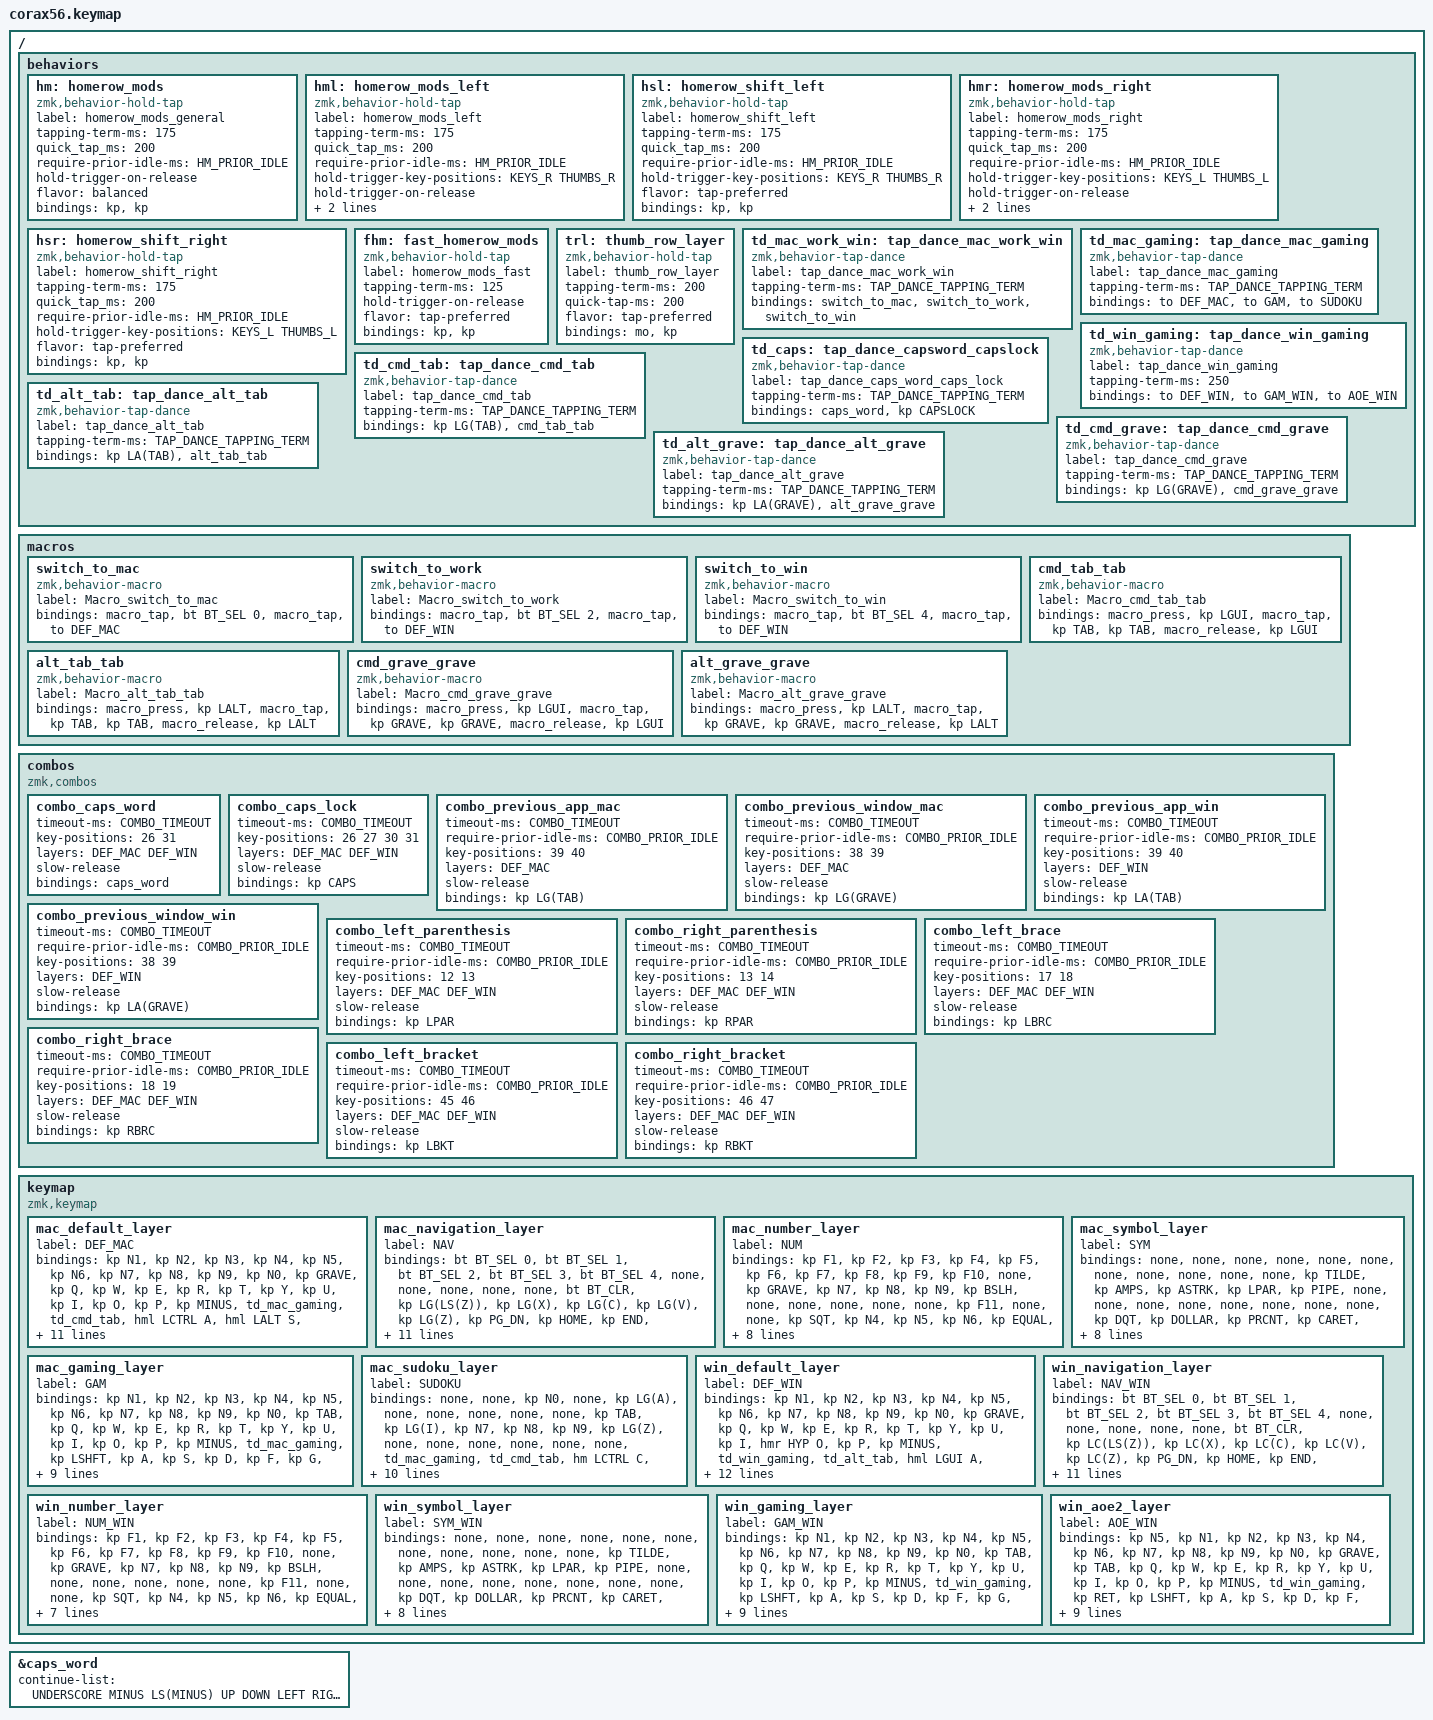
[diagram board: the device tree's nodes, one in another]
#include <behaviors.dtsi>
#include <dt-bindings/zmk/keys.h>
#include <dt-bindings/zmk/bt.h>
#include <dt-bindings/zmk/outputs.h>
#include <dt-bindings/zmk/ext_power.h>

#define DEF_MAC 0
#define NAV     1
#define NUM     2
#define SYM     3
#define GAM     4
#define SUDOKU  5
#define DEF_WIN 6
#define NAV_WIN 7
#define NUM_WIN 8
#define SYM_WIN 9
#define GAM_WIN 10
#define AOE_WIN 11

// Timing constants and Hyper/Meh keys
#define HYP LC(LA(LS(LGUI)))
#define MEH LC(LA(LSHFT))
#define LEADER F12
#define COMBO_TIMEOUT 25
#define COMBO_PRIOR_IDLE 100
#define HM_PRIOR_IDLE 75
#define TAP_DANCE_TAPPING_TERM 250

#define KEYS_L 0 1 2 3 4 10 11 12 13 14 15 22 23 24 25 26 27 28 36 37 38 39 40 41 42 // left-hand keys
#define KEYS_R 5 6 7 8 9 16 17 18 19 20 21 29 30 31 32 33 34 35 43 44 45 46 47 48 49 // right-hand keys
#define THUMBS_L 50 51 52 53 // left-hand thumb keys
#define THUMBS_R 54 55 56 57 // right-hand thumb keys

// Caps word will continue to remain active after these keys
&caps_word {
    continue-list = <UNDERSCORE MINUS LS(MINUS) UP DOWN LEFT RIGHT BSPC DEL>;
};

/ {

    behaviors {

        // Homerow Mods allowing use of modifiers on the home row
        hm: homerow_mods {
            compatible = "zmk,behavior-hold-tap";
            label = "homerow_mods_general";
            #binding-cells = <2>;
            tapping-term-ms = <175>;
            quick_tap_ms = <200>;
            require-prior-idle-ms = <HM_PRIOR_IDLE>;
            hold-trigger-on-release;
            flavor = "balanced";
            bindings = <&kp>, <&kp>;
        };

        hml: homerow_mods_left {
            compatible = "zmk,behavior-hold-tap";
            label = "homerow_mods_left";
            #binding-cells = <2>;
            tapping-term-ms = <175>;
            quick_tap_ms = <200>;
            require-prior-idle-ms = <HM_PRIOR_IDLE>;
            hold-trigger-key-positions = <KEYS_R THUMBS_R>;
            hold-trigger-on-release;
            flavor = "balanced";
            bindings = <&kp>, <&kp>;
        };

        hsl: homerow_shift_left {
            compatible = "zmk,behavior-hold-tap";
            label = "homerow_shift_left";
            #binding-cells = <2>;
            tapping-term-ms = <175>;
            quick_tap_ms = <200>;
            require-prior-idle-ms = <HM_PRIOR_IDLE>;
            hold-trigger-key-positions = <KEYS_R THUMBS_R>;
            flavor = "tap-preferred";
            bindings = <&kp>, <&kp>;
        };

        hmr: homerow_mods_right {
            compatible = "zmk,behavior-hold-tap";
            label = "homerow_mods_right";
            #binding-cells = <2>;
            tapping-term-ms = <175>;
            quick_tap_ms = <200>;
            require-prior-idle-ms = <HM_PRIOR_IDLE>;
            hold-trigger-key-positions = <KEYS_L THUMBS_L>;
            hold-trigger-on-release;
            flavor = "balanced";
            bindings = <&kp>, <&kp>;
        };

        hsr: homerow_shift_right {
            compatible = "zmk,behavior-hold-tap";
            label = "homerow_shift_right";
            #binding-cells = <2>;
            tapping-term-ms = <175>;
            quick_tap_ms = <200>;
            require-prior-idle-ms = <HM_PRIOR_IDLE>;
            hold-trigger-key-positions = <KEYS_L THUMBS_L>;
            flavor = "tap-preferred";
            bindings = <&kp>, <&kp>;
        };

        fhm: fast_homerow_mods {
            compatible = "zmk,behavior-hold-tap";
            label = "homerow_mods_fast";
            #binding-cells = <2>;
            tapping-term-ms = <125>;
            hold-trigger-on-release;
            flavor = "tap-preferred";
            bindings = <&kp>, <&kp>;
        };

        // Layers that are activated when holding a thumb row key
        trl: thumb_row_layer {
            compatible = "zmk,behavior-hold-tap";
            label = "thumb_row_layer";
            #binding-cells = <2>;
            tapping-term-ms = <200>;
            quick-tap-ms = <200>;
            flavor = "tap-preferred";
            bindings = <&mo>, <&kp>;
        };

        // Tap-dance allowing easy switch between mac and windows
        td_mac_work_win: tap_dance_mac_work_win {
            compatible = "zmk,behavior-tap-dance";
            label = "tap_dance_mac_work_win";
            #binding-cells = <0>;
            tapping-term-ms = <TAP_DANCE_TAPPING_TERM>;
            bindings = <&switch_to_mac>, <&switch_to_work>, <&switch_to_win>;
        };

        // Tap-dance allowing easy switch between mac default layer, gaming and sudoku layer
        td_mac_gaming: tap_dance_mac_gaming {
            compatible = "zmk,behavior-tap-dance";
            label = "tap_dance_mac_gaming";
            #binding-cells = <0>;
            tapping-term-ms = <TAP_DANCE_TAPPING_TERM>;
            bindings = <&to DEF_MAC>, <&to GAM>, <&to SUDOKU>;
        };

        // Tap-dance allowing easy switch between windows default layer and gaming layer
        td_win_gaming: tap_dance_win_gaming {
            compatible = "zmk,behavior-tap-dance";
            label = "tap_dance_win_gaming";
            #binding-cells = <0>;
            tapping-term-ms = <250>;
            bindings = <&to DEF_WIN>, <&to GAM_WIN>, <&to AOE_WIN>;
        };

        // Tap-dance allowing easy switch between capsword and capslock
        td_caps: tap_dance_capsword_capslock {
            compatible = "zmk,behavior-tap-dance";
            label = "tap_dance_caps_word_caps_lock";
            #binding-cells = <0>;
            tapping-term-ms = <TAP_DANCE_TAPPING_TERM>;
            bindings = <&caps_word>, <&kp CAPSLOCK>;
        };

        // Tap-dance to quickly switch between last and second-to-last used applications on mac
        td_cmd_tab: tap_dance_cmd_tab {
            compatible = "zmk,behavior-tap-dance";
            label = "tap_dance_cmd_tab";
            #binding-cells = <0>;
            tapping-term-ms = <TAP_DANCE_TAPPING_TERM>;
            bindings = <&kp LG(TAB)>, <&cmd_tab_tab>;
        };

        // Tap-dance to quickly switch between last and second-to-last used applications on windows
        td_alt_tab: tap_dance_alt_tab {
            compatible = "zmk,behavior-tap-dance";
            label = "tap_dance_alt_tab";
            #binding-cells = <0>;
            tapping-term-ms = <TAP_DANCE_TAPPING_TERM>;
            bindings = <&kp LA(TAB)>, <&alt_tab_tab>;
        };

        // Tap-dance to quickly switch between last and second-to-last used window of current application on mac
        td_cmd_grave: tap_dance_cmd_grave {
            compatible = "zmk,behavior-tap-dance";
            label = "tap_dance_cmd_grave";
            #binding-cells = <0>;
            tapping-term-ms = <TAP_DANCE_TAPPING_TERM>;
            bindings = <&kp LG(GRAVE)>, <&cmd_grave_grave>;
        };

        // Tap-dance to quickly switch between last and second-to-last used window of current application on windows
        td_alt_grave: tap_dance_alt_grave {
            compatible = "zmk,behavior-tap-dance";
            label = "tap_dance_alt_grave";
            #binding-cells = <0>;
            tapping-term-ms = <TAP_DANCE_TAPPING_TERM>;
            bindings = <&kp LA(GRAVE)>, <&alt_grave_grave>;
        };

    };

    macros {

        // Macro to select mac bluetooth profile and switch to default mac layer
        switch_to_mac: switch_to_mac {
            label = "Macro_switch_to_mac";
            compatible = "zmk,behavior-macro";
            #binding-cells = <0>;
            bindings = <&macro_tap &bt BT_SEL 0> , <&macro_tap &to DEF_MAC> ;
        };

        // Macro to select mac bluetooth profile and switch to default work layer
        switch_to_work: switch_to_work {
            label = "Macro_switch_to_work";
            compatible = "zmk,behavior-macro";
            #binding-cells = <0>;
            bindings = <&macro_tap &bt BT_SEL 2> , <&macro_tap &to DEF_WIN> ;
        };

        // Macro to select windows bluetooth profile and switch to default windows layer
        switch_to_win: switch_to_win {
            label = "Macro_switch_to_win";
            compatible = "zmk,behavior-macro";
            #binding-cells = <0>;
            bindings = <&macro_tap &bt BT_SEL 4> , <&macro_tap &to DEF_WIN> ;
        };

        // Macro to switch to second-to-last used application on mac
        cmd_tab_tab: cmd_tab_tab {
            label = "Macro_cmd_tab_tab";
            compatible = "zmk,behavior-macro";
            #binding-cells = <0>;
            bindings = <&macro_press &kp LGUI> , <&macro_tap &kp TAB &kp TAB> , <&macro_release &kp LGUI> ;
        };

        // Macro to switch to second-to-last used application on windows
        alt_tab_tab: alt_tab_tab {
            label = "Macro_alt_tab_tab";
            compatible = "zmk,behavior-macro";
            #binding-cells = <0>;
            bindings = <&macro_press &kp LALT> , <&macro_tap &kp TAB &kp TAB> , <&macro_release &kp LALT> ;
        };

        // Macro to switch to second-to-last used window of current application on mac
        cmd_grave_grave: cmd_grave_grave {
            label = "Macro_cmd_grave_grave";
            compatible = "zmk,behavior-macro";
            #binding-cells = <0>;
            bindings = <&macro_press &kp LGUI> , <&macro_tap &kp GRAVE &kp GRAVE> , <&macro_release &kp LGUI> ;
        };

        // Macro to switch to second-to-last used window of current application on windows
        alt_grave_grave: alt_grave_grave {
            label = "Macro_alt_grave_grave";
            compatible = "zmk,behavior-macro";
            #binding-cells = <0>;
            bindings = <&macro_press &kp LALT> , <&macro_tap &kp GRAVE &kp GRAVE> , <&macro_release &kp LALT> ;
        };

    };

    combos {

        compatible = "zmk,combos";

        // Simultaneous D+K : Turn on caps_word
        combo_caps_word {
            timeout-ms = <COMBO_TIMEOUT>;
            key-positions = <26 31>;
            layers = <DEF_MAC DEF_WIN>;
			slow-release;
            bindings = <&caps_word>;
        };

        // Simultaneous D+F+J+K : Toggle Caps Lock
        combo_caps_lock {
            timeout-ms = <COMBO_TIMEOUT>;
            key-positions = <26 27 30 31>;
            layers = <DEF_MAC DEF_WIN>;
			slow-release;
            bindings = <&kp CAPS>;
        };

        // Simultaneous C+V : Switch to previous app on mac
        combo_previous_app_mac {
            timeout-ms = <COMBO_TIMEOUT>;
            require-prior-idle-ms = <COMBO_PRIOR_IDLE>;
            key-positions = <39 40>;
            layers = <DEF_MAC>;
			slow-release;
            bindings = <&kp LG(TAB)>;
        };

        // Simultaneous X+C : Switch to previous window of current app on mac
        combo_previous_window_mac {
            timeout-ms = <COMBO_TIMEOUT>;
            require-prior-idle-ms = <COMBO_PRIOR_IDLE>;
            key-positions = <38 39>;
            layers = <DEF_MAC>;
			slow-release;
            bindings = <&kp LG(GRAVE)>;
        };

        // Simultaneous C+V : Switch to previous app on win
        combo_previous_app_win {
            timeout-ms = <COMBO_TIMEOUT>;
            require-prior-idle-ms = <COMBO_PRIOR_IDLE>;
            key-positions = <39 40>;
            layers = <DEF_WIN>;
			slow-release;
            bindings = <&kp LA(TAB)>;
        };

        // Simultaneous X+C : Switch to previous window of current app on win
        combo_previous_window_win {
            timeout-ms = <COMBO_TIMEOUT>;
            require-prior-idle-ms = <COMBO_PRIOR_IDLE>;
            key-positions = <38 39>;
            layers = <DEF_WIN>;
			slow-release;
            bindings = <&kp LA(GRAVE)>;
        };

        // Simultaneous W+E : Type (
        combo_left_parenthesis {
            timeout-ms = <COMBO_TIMEOUT>;
            require-prior-idle-ms = <COMBO_PRIOR_IDLE>;
            key-positions = <12 13>;
            layers = <DEF_MAC DEF_WIN>;
			slow-release;
            bindings = <&kp LPAR>;
        };

        // Simultaneous E+R : Type )
        combo_right_parenthesis {
            timeout-ms = <COMBO_TIMEOUT>;
            require-prior-idle-ms = <COMBO_PRIOR_IDLE>;
            key-positions = <13 14>;
            layers = <DEF_MAC DEF_WIN>;
			slow-release;
            bindings = <&kp RPAR>;
        };

        // Simultaneous U+I : Type {
        combo_left_brace {
            timeout-ms = <COMBO_TIMEOUT>;
            require-prior-idle-ms = <COMBO_PRIOR_IDLE>;
            key-positions = <17 18>;
            layers = <DEF_MAC DEF_WIN>;
			slow-release;
            bindings = <&kp LBRC>;
        };

        // Simultaneous I+O : Type }
        combo_right_brace {
            timeout-ms = <COMBO_TIMEOUT>;
            require-prior-idle-ms = <COMBO_PRIOR_IDLE>;
            key-positions = <18 19>;
            layers = <DEF_MAC DEF_WIN>;
			slow-release;
            bindings = <&kp RBRC>;
        };

        // Simultaneous m+, : Type [
        combo_left_bracket {
            timeout-ms = <COMBO_TIMEOUT>;
            require-prior-idle-ms = <COMBO_PRIOR_IDLE>;
            key-positions = <45 46>;
            layers = <DEF_MAC DEF_WIN>;
			slow-release;
            bindings = <&kp LBKT>;
        };

        // Simultaneous ,+. : Type ]
        combo_right_bracket {
            timeout-ms = <COMBO_TIMEOUT>;
            require-prior-idle-ms = <COMBO_PRIOR_IDLE>;
            key-positions = <46 47>;
            layers = <DEF_MAC DEF_WIN>;
			slow-release;
            bindings = <&kp RBKT>;
        };

    };

    keymap {
        compatible = "zmk,keymap";

        mac_default_layer {
            label = "DEF_MAC";
            bindings = <
//                                     ┌─────────────┬─────────────┬──────────────────┬─────────────┬─────────────┐                              ┌──────────────┬────────────────┬──────────────────┬─────────────┬─────────────┐
//                                     │      1      │      2      │        3         │      4      │      5      │                              │      6       │       7        │        8         │      9      │      0      │
//                     ┌───────────────┼─────────────┼─────────────┼──────────────────┼─────────────┼─────────────┤                              ├──────────────┼────────────────┼──────────────────┼─────────────┼─────────────┼───┐
//                     │       `       │      Q      │      W      │        E         │      R      │      T      │                              │      Y       │       U        │        I         │      O      │      P      │ - │
//    ┌────────────────┼───────────────┼─────────────┼─────────────┼──────────────────┼─────────────┼─────────────┤                              ├──────────────┼────────────────┼──────────────────┼─────────────┼─────────────┼───┼───┐
//    │ &td_mac_gaming │  &td_cmd_tab  │ &hml lctl A │ &hml lalt S │   &hsl lsft D    │ &hml lgui F │ &hml MEH G  │                              │  &hmr MEH H  │  &hmr rgui J   │   &hsr rsft K    │ &hmr ralt L │ &hmr rctl ; │ ' │ = │
//    └────────────────┼───────────────┼─────────────┼─────────────┼──────────────────┼─────────────┼─────────────┼──────────────┬───────────────┼──────────────┼────────────────┼──────────────────┼─────────────┼─────────────┼───┼───┘
//                     │ &td_cmd_grave │      Z      │      X      │        C         │      V      │      B      │     mute     │     play      │      N       │       M        │        ,         │      .      │      /      │ \ │
//                     └───────────────┴─────────────┴─────────────┼──────────────────┼─────────────┼─────────────┼──────────────┼───────────────┼──────────────┼────────────────┼──────────────────┼─────────────┴─────────────┴───┘
//                                                                 │ &td_mac_work_win │     esc     │ &hm HYP tab │ &trl NAV spc │ &trl NUM bspc │ &trl SYM ent │ &hm HYP LEADER │ &td_mac_work_win │
//                                                                 └──────────────────┴─────────────┴─────────────┴──────────────┴───────────────┴──────────────┴────────────────┴──────────────────┘
                                   &kp N1         &kp N2        &kp N3             &kp N4        &kp N5                                            &kp N6         &kp N7           &kp N8             &kp N9        &kp N0
                   &kp GRAVE       &kp Q          &kp W         &kp E              &kp R         &kp T                                             &kp Y          &kp U            &kp I              &kp O         &kp P             &kp MINUS
  &td_mac_gaming   &td_cmd_tab     &hml LCTRL A   &hml LALT S   &hsl LSHFT D       &hml LGUI F   &hml MEH G                                        &hmr MEH H     &hmr RGUI J      &hsr RSHFT K       &hmr RALT L   &hmr RCTRL SEMI   &kp SQT     &kp EQUAL
                   &td_cmd_grave   &kp Z          &kp X         &kp C              &kp V         &kp B         &kp C_MUTE       &kp C_PLAY_PAUSE   &kp N          &kp M            &kp COMMA          &kp DOT       &kp FSLH          &kp BSLH
                                                                &td_mac_work_win   &kp ESC       &hm HYP TAB   &trl NAV SPACE   &trl NUM BSPC      &trl SYM RET   &hm HYP LEADER   &td_mac_work_win
            >;

            sensor-bindings = <&inc_dec_kp C_VOL_DN C_VOL_UP &inc_dec_kp C_BRI_DN C_BRI_UP>;
        };

		mac_navigation_layer {
            label = "NAV";
            bindings = <
//                            ┌───────────────┬──────────┬──────────┬──────────┬──────────┐             ┌──────────────────┬────────────┬────────────┬──────────────────┬──────┐
//                            │   bt_sel 0    │ bt_sel 1 │ bt_sel 2 │ bt_sel 3 │ bt_sel 4 │             │                  │            │            │                  │      │
//                 ┌──────────┼───────────────┼──────────┼──────────┼──────────┼──────────┤             ├──────────────────┼────────────┼────────────┼──────────────────┼──────┼───────────┐
//                 │  bt_clr  │ lgui(lsft(Z)) │ lgui(X)  │ lgui(C)  │ lgui(V)  │ lgui(Z)  │             │       pgdn       │    home    │    end     │       pgup       │      │ epwr_ tog │
//    ┌────────────┼──────────┼───────────────┼──────────┼──────────┼──────────┼──────────┤             ├──────────────────┼────────────┼────────────┼──────────────────┼──────┼───────────┼─────┐
//    │ &sys_reset │          │     lctl      │   lalt   │   lsft   │   lgui   │   MEH    │             │       left       │    down    │     up     │       rght       │ pscr │           │     │
//    └────────────┼──────────┼───────────────┼──────────┼──────────┼──────────┼──────────┼──────┬──────┼──────────────────┼────────────┼────────────┼──────────────────┼──────┼───────────┼─────┘
//                 │ out_ tog │     bspc      │   esc    │   tab    │   spc    │   ent    │ boot │ boot │ lsft(lalt(left)) │ lalt(left) │ lalt(rght) │ lsft(lalt(rght)) │ pwr  │ term_lock │
//                 └──────────┴───────────────┴──────────┼──────────┼──────────┼──────────┼──────┼──────┼──────────────────┼────────────┼────────────┼──────────────────┴──────┴───────────┘
//                                                       │          │          │          │      │ bspc │       ent        │    del     │            │
//                                                       └──────────┴──────────┴──────────┴──────┴──────┴──────────────────┴────────────┴────────────┘
                              &bt BT_SEL 0    &bt BT_SEL 1   &bt BT_SEL 2   &bt BT_SEL 3   &bt BT_SEL 4                               &none              &none          &none           &none               &none
               &bt BT_CLR     &kp LG(LS(Z))   &kp LG(X)      &kp LG(C)      &kp LG(V)      &kp LG(Z)                                  &kp PG_DN          &kp HOME       &kp END         &kp PG_UP           &none         &ext_power EP_TOG
  &sys_reset   &none          &kp LCTRL       &kp LALT       &kp LSHFT      &kp LGUI       &kp MEH                                    &kp LEFT           &kp DOWN       &kp UP          &kp RIGHT           &kp PSCRN     &none               &none
               &out OUT_TOG   &kp BSPC        &kp ESC        &kp TAB        &kp SPACE      &kp RET        &bootloader   &bootloader   &kp LS(LA(LEFT))   &kp LA(LEFT)   &kp LA(RIGHT)   &kp LS(LA(RIGHT))   &kp C_POWER   &kp C_AL_LOCK
                                                             &none          &none          &none          &none         &kp BSPC      &kp RET            &kp DEL        &none
            >;

            sensor-bindings = <&inc_dec_kp C_VOL_DN C_VOL_UP &inc_dec_kp PG_DN PG_UP>;
        };

		mac_number_layer {
            label = "NUM";
			bindings = <
//                ┌────┬────┬─────┬─────┬────┐           ┌─────┬──────┬──────┬──────┬──────┐
//                │ f1 │ f2 │ f3  │ f4  │ f5 │           │ f6  │  f7  │  f8  │  f9  │ f10  │
//          ┌─────┼────┼────┼─────┼─────┼────┤           ├─────┼──────┼──────┼──────┼──────┼─────┐
//          │     │ `  │ 7  │  8  │  9  │ \  │           │     │      │      │      │      │ f11 │
//    ┌─────┼─────┼────┼────┼─────┼─────┼────┤           ├─────┼──────┼──────┼──────┼──────┼─────┼─────┐
//    │     │     │ '  │ 4  │  5  │  6  │ =  │           │ MEH │ rgui │ rsft │ ralt │ rctl │     │ f12 │
//    └─────┼─────┼────┼────┼─────┼─────┼────┼─────┬─────┼─────┼──────┼──────┼──────┼──────┼─────┼─────┘
//          │     │ [  │ 1  │  2  │  3  │ ]  │     │     │     │      │      │      │      │     │
//          └─────┴────┴────┼─────┼─────┼────┼─────┼─────┼─────┼──────┼──────┼──────┴──────┴─────┘
//                          │     │ esc │ -  │  0  │     │     │      │      │
//                          └─────┴─────┴────┴─────┴─────┴─────┴──────┴──────┘
                  &kp F1      &kp F2   &kp F3   &kp F4    &kp F5                       &kp F6    &kp F7     &kp F8      &kp F9     &kp F10
          &none   &kp GRAVE   &kp N7   &kp N8   &kp N9    &kp BSLH                     &none     &none      &none       &none      &none       &kp F11
  &none   &none   &kp SQT     &kp N4   &kp N5   &kp N6    &kp EQUAL                    &kp MEH   &kp RGUI   &kp RSHFT   &kp RALT   &kp RCTRL   &none     &kp F12
          &none   &kp LBKT    &kp N1   &kp N2   &kp N3    &kp RBKT    &none    &none   &none     &none      &none       &none      &none       &none
                                       &none    &kp ESC   &kp MINUS   &kp N0   &none   &none     &none      &none
			>;

            sensor-bindings = <&inc_dec_kp C_VOL_DN C_VOL_UP &inc_dec_kp C_BRI_DN C_BRI_UP>;
		};

		mac_symbol_layer {
            label = "SYM";
			bindings = <
//                ┌─────┬─────┬─────┬─────┬─────┐           ┌─────┬──────┬──────┬──────┬──────┐
//                │     │     │     │     │     │           │     │      │      │      │      │
//          ┌─────┼─────┼─────┼─────┼─────┼─────┤           ├─────┼──────┼──────┼──────┼──────┼─────┐
//          │     │  ~  │  &  │  *  │  (  │  |  │           │     │      │      │      │      │     │
//    ┌─────┼─────┼─────┼─────┼─────┼─────┼─────┤           ├─────┼──────┼──────┼──────┼──────┼─────┼─────┐
//    │     │     │  "  │  $  │  %  │  ^  │  +  │           │ MEH │ rgui │ rsft │ ralt │ rctl │     │     │
//    └─────┼─────┼─────┼─────┼─────┼─────┼─────┼─────┬─────┼─────┼──────┼──────┼──────┼──────┼─────┼─────┘
//          │     │  {  │  !  │  @  │  #  │  }  │     │     │     │      │      │      │      │     │
//          └─────┴─────┴─────┼─────┼─────┼─────┼─────┼─────┼─────┼──────┼──────┼──────┴──────┴─────┘
//                            │     │ esc │  _  │  )  │     │     │      │      │
//                            └─────┴─────┴─────┴─────┴─────┴─────┴──────┴──────┘
                  &none       &none        &none       &none       &none                          &none     &none      &none       &none      &none
          &none   &kp TILDE   &kp AMPS     &kp ASTRK   &kp LPAR    &kp PIPE                       &none     &none      &none       &none      &none       &none
  &none   &none   &kp DQT     &kp DOLLAR   &kp PRCNT   &kp CARET   &kp PLUS                       &kp MEH   &kp RGUI   &kp RSHFT   &kp RALT   &kp RCTRL   &none   &none
          &none   &kp LBRC    &kp EXCL     &kp AT      &kp HASH    &kp RBRC    &none      &none   &none     &none      &none       &none      &none       &none
                                           &none       &kp ESC     &kp UNDER   &kp RPAR   &none   &none     &none      &none
			>;

            sensor-bindings = <&inc_dec_kp C_VOL_DN C_VOL_UP &inc_dec_kp C_BRI_DN C_BRI_UP>;
        };

		mac_gaming_layer {
            label = "GAM";
			bindings = <
//                            ┌───┬───┬──────────────────┬──────────────┬──────────────┐                              ┌──────────────┬────────┬──────────────────┬───┬───┐
//                            │ 1 │ 2 │        3         │      4       │      5       │                              │      6       │   7    │        8         │ 9 │ 0 │
//                     ┌──────┼───┼───┼──────────────────┼──────────────┼──────────────┤                              ├──────────────┼────────┼──────────────────┼───┼───┼───┐
//                     │ tab  │ Q │ W │        E         │      R       │      T       │                              │      Y       │   U    │        I         │ O │ P │ - │
//    ┌────────────────┼──────┼───┼───┼──────────────────┼──────────────┼──────────────┤                              ├──────────────┼────────┼──────────────────┼───┼───┼───┼───┐
//    │ &td_mac_gaming │ lsft │ A │ S │        D         │      F       │      G       │                              │      H       │   J    │        K         │ L │ ; │ ' │ = │
//    └────────────────┼──────┼───┼───┼──────────────────┼──────────────┼──────────────┼──────────────┬───────────────┼──────────────┼────────┼──────────────────┼───┼───┼───┼───┘
//                     │ lctl │ Z │ X │        C         │      V       │      B       │     ent      │               │      N       │   M    │        ,         │ . │ / │ \ │
//                     └──────┴───┴───┼──────────────────┼──────────────┼──────────────┼──────────────┼───────────────┼──────────────┼────────┼──────────────────┼───┴───┴───┘
//                                    │ &td_mac_work_win │ &hm lalt esc │ &hm lgui ent │ &hm lsft spc │ &trl NUM bspc │ &trl SYM ent │ LEADER │ &td_mac_work_win │
//                                    └──────────────────┴──────────────┴──────────────┴──────────────┴───────────────┴──────────────┴────────┴──────────────────┘
                               &kp N1   &kp N2   &kp N3             &kp N4         &kp N5                                           &kp N6         &kp N7       &kp N8             &kp N9    &kp N0
                   &kp TAB     &kp Q    &kp W    &kp E              &kp R          &kp T                                            &kp Y          &kp U        &kp I              &kp O     &kp P      &kp MINUS
  &td_mac_gaming   &kp LSHFT   &kp A    &kp S    &kp D              &kp F          &kp G                                            &kp H          &kp J        &kp K              &kp L     &kp SEMI   &kp SQT     &kp EQUAL
                   &kp LCTRL   &kp Z    &kp X    &kp C              &kp V          &kp B          &kp RET           &none           &kp N          &kp M        &kp COMMA          &kp DOT   &kp FSLH   &kp BSLH
                                                 &td_mac_work_win   &hm LALT ESC   &hm LGUI RET   &hm LSHFT SPACE   &trl NUM BSPC   &trl SYM RET   &kp LEADER   &td_mac_work_win
			>;

            sensor-bindings = <&inc_dec_kp C_VOL_DN C_VOL_UP &inc_dec_kp C_BRI_DN C_BRI_UP>;
		};

		mac_sudoku_layer {
            label = "SUDOKU";
			bindings = <
//                                   ┌──────────────────┬─────┬──────────────────┬──────────────┬────────────┐                            ┌──────────────┬──────┬──────────────────┬──────┬─────┐
//                                   │                  │     │        0         │              │  lgui(A)   │                            │              │      │                  │      │     │
//                     ┌─────────────┼──────────────────┼─────┼──────────────────┼──────────────┼────────────┤                            ├──────────────┼──────┼──────────────────┼──────┼─────┼─────┐
//                     │     tab     │     lgui(I)      │  7  │        8         │      9       │  lgui(Z)   │                            │              │      │                  │      │     │     │
//    ┌────────────────┼─────────────┼──────────────────┼─────┼──────────────────┼──────────────┼────────────┤                            ├──────────────┼──────┼──────────────────┼──────┼─────┼─────┼─────┐
//    │ &td_mac_gaming │ &td_cmd_tab │    &hm lctl C    │  4  │        5         │  &hm lgui 6  │    bspc    │                            │     left     │ down │        up        │ rght │     │     │     │
//    └────────────────┼─────────────┼──────────────────┼─────┼──────────────────┼──────────────┼────────────┼────────────┬───────────────┼──────────────┼──────┼──────────────────┼──────┼─────┼─────┼─────┘
//                     │             │ &hm lgui(lsft) V │  1  │        2         │      3       │     S      │    mute    │     play      │              │      │                  │      │     │     │
//                     └─────────────┴──────────────────┴─────┼──────────────────┼──────────────┼────────────┼────────────┼───────────────┼──────────────┼──────┼──────────────────┼──────┴─────┴─────┘
//                                                            │ &td_mac_work_win │ &hm lalt esc │ &hm lsft X │ &hm lgui Z │ &trl NUM bspc │ &trl SYM ent │ del  │ &td_mac_work_win │
//                                                            └──────────────────┴──────────────┴────────────┴────────────┴───────────────┴──────────────┴──────┴──────────────────┘
                                 &none             &none    &kp N0             &none          &kp LG(A)                                     &none          &none      &none              &none       &none
                   &kp TAB       &kp LG(I)         &kp N7   &kp N8             &kp N9         &kp LG(Z)                                     &none          &none      &none              &none       &none   &none
  &td_mac_gaming   &td_cmd_tab   &hm LCTRL C       &kp N4   &kp N5             &hm LGUI N6    &kp BSPC                                      &kp LEFT       &kp DOWN   &kp UP             &kp RIGHT   &none   &none   &none
                   &none         &hm LG(LSHFT) V   &kp N1   &kp N2             &kp N3         &kp S         &kp C_MUTE   &kp C_PLAY_PAUSE   &none          &none      &none              &none       &none   &none
                                                            &td_mac_work_win   &hm LALT ESC   &hm LSHFT X   &hm LGUI Z   &trl NUM BSPC      &trl SYM RET   &kp DEL    &td_mac_work_win
			>;

            sensor-bindings = <&inc_dec_kp C_VOL_DN C_VOL_UP &inc_dec_kp C_BRI_DN C_BRI_UP>;
		};

		win_default_layer {
            label = "DEF_WIN";
			bindings = <
//                                     ┌─────────────┬─────────────┬──────────────────┬─────────────┬─────────────┐                                      ┌──────────────────┬────────────────┬──────────────────┬─────────────┬─────────────┐
//                                     │      1      │      2      │        3         │      4      │      5      │                                      │        6         │       7        │        8         │      9      │      0      │
//                     ┌───────────────┼─────────────┼─────────────┼──────────────────┼─────────────┼─────────────┤                                      ├──────────────────┼────────────────┼──────────────────┼─────────────┼─────────────┼───┐
//                     │       `       │      Q      │      W      │        E         │      R      │      T      │                                      │        Y         │       U        │        I         │ &hmr HYP O  │      P      │ - │
//    ┌────────────────┼───────────────┼─────────────┼─────────────┼──────────────────┼─────────────┼─────────────┤                                      ├──────────────────┼────────────────┼──────────────────┼─────────────┼─────────────┼───┼───┐
//    │ &td_win_gaming │  &td_alt_tab  │ &hml lgui A │ &hml lalt S │   &hsl lsft D    │ &hml lctl F │ &hml MEH G  │                                      │    &hmr MEH H    │  &hmr lctl J   │   &hsr lsft K    │ &hmr lalt L │ &hmr lgui ; │ ' │ = │
//    └────────────────┼───────────────┼─────────────┼─────────────┼──────────────────┼─────────────┼─────────────┼──────────────────┬───────────────────┼──────────────────┼────────────────┼──────────────────┼─────────────┼─────────────┼───┼───┘
//                     │ &td_alt_grave │      Z      │      X      │        C         │      V      │      B      │       mute       │       play        │        N         │       M        │        ,         │      .      │      /      │ \ │
//                     └───────────────┴─────────────┴─────────────┼──────────────────┼─────────────┼─────────────┼──────────────────┼───────────────────┼──────────────────┼────────────────┼──────────────────┼─────────────┴─────────────┴───┘
//                                                                 │ &td_mac_work_win │     esc     │ &hm HYP tab │ &trl NAV_WIN spc │ &trl NUM_WIN bspc │ &trl SYM_WIN ent │ &hm HYP LEADER │ &td_mac_work_win │
//                                                                 └──────────────────┴─────────────┴─────────────┴──────────────────┴───────────────────┴──────────────────┴────────────────┴──────────────────┘
                                   &kp N1        &kp N2        &kp N3             &kp N4         &kp N5                                                 &kp N6             &kp N7           &kp N8             &kp N9        &kp N0
                   &kp GRAVE       &kp Q         &kp W         &kp E              &kp R          &kp T                                                  &kp Y              &kp U            &kp I              &hmr HYP O    &kp P            &kp MINUS
  &td_win_gaming   &td_alt_tab     &hml LGUI A   &hml LALT S   &hsl LSHFT D       &hml LCTRL F   &hml MEH G                                             &hmr MEH H         &hmr LCTRL J     &hsr LSHFT K       &hmr LALT L   &hmr LGUI SEMI   &kp SQT     &kp EQUAL
                   &td_alt_grave   &kp Z         &kp X         &kp C              &kp V          &kp B         &kp C_MUTE           &kp C_PLAY_PAUSE    &kp N              &kp M            &kp COMMA          &kp DOT       &kp FSLH         &kp BSLH
                                                               &td_mac_work_win   &kp ESC        &hm HYP TAB   &trl NAV_WIN SPACE   &trl NUM_WIN BSPC   &trl SYM_WIN RET   &hm HYP LEADER   &td_mac_work_win
			>;

            sensor-bindings = <&inc_dec_kp C_VOL_DN C_VOL_UP &inc_dec_kp C_BRI_DN C_BRI_UP>;
		};

		win_navigation_layer {
            label = "NAV_WIN";
            bindings = <
//                            ┌───────────────┬──────────┬──────────┬──────────┬──────────┐             ┌──────────────────┬────────────┬────────────┬──────────────────┬──────┐
//                            │   bt_sel 0    │ bt_sel 1 │ bt_sel 2 │ bt_sel 3 │ bt_sel 4 │             │                  │            │            │                  │      │
//                 ┌──────────┼───────────────┼──────────┼──────────┼──────────┼──────────┤             ├──────────────────┼────────────┼────────────┼──────────────────┼──────┼───────────┐
//                 │  bt_clr  │ lctl(lsft(Z)) │ lctl(X)  │ lctl(C)  │ lctl(V)  │ lctl(Z)  │             │       pgdn       │    home    │    end     │       pgup       │      │ epwr_ tog │
//    ┌────────────┼──────────┼───────────────┼──────────┼──────────┼──────────┼──────────┤             ├──────────────────┼────────────┼────────────┼──────────────────┼──────┼───────────┼─────┐
//    │ &sys_reset │          │     lctl      │   lalt   │   lsft   │   lgui   │   MEH    │             │       left       │    down    │     up     │       rght       │ pscr │           │     │
//    └────────────┼──────────┼───────────────┼──────────┼──────────┼──────────┼──────────┼──────┬──────┼──────────────────┼────────────┼────────────┼──────────────────┼──────┼───────────┼─────┘
//                 │ out_ tog │     bspc      │   esc    │   tab    │   spc    │   ent    │ boot │ boot │ lsft(lctl(left)) │ lctl(left) │ lctl(rght) │ lsft(lctl(rght)) │ pwr  │ term_lock │
//                 └──────────┴───────────────┴──────────┼──────────┼──────────┼──────────┼──────┼──────┼──────────────────┼────────────┼────────────┼──────────────────┴──────┴───────────┘
//                                                       │          │          │          │      │ bspc │       ent        │    del     │            │
//                                                       └──────────┴──────────┴──────────┴──────┴──────┴──────────────────┴────────────┴────────────┘
                              &bt BT_SEL 0    &bt BT_SEL 1   &bt BT_SEL 2   &bt BT_SEL 3   &bt BT_SEL 4                               &none              &none          &none           &none               &none
               &bt BT_CLR     &kp LC(LS(Z))   &kp LC(X)      &kp LC(C)      &kp LC(V)      &kp LC(Z)                                  &kp PG_DN          &kp HOME       &kp END         &kp PG_UP           &none         &ext_power EP_TOG
  &sys_reset   &none          &kp LCTRL       &kp LALT       &kp LSHFT      &kp LGUI       &kp MEH                                    &kp LEFT           &kp DOWN       &kp UP          &kp RIGHT           &kp PSCRN     &none               &none
               &out OUT_TOG   &kp BSPC        &kp ESC        &kp TAB        &kp SPACE      &kp RET        &bootloader   &bootloader   &kp LS(LC(LEFT))   &kp LC(LEFT)   &kp LC(RIGHT)   &kp LS(LC(RIGHT))   &kp C_POWER   &kp C_AL_LOCK
                                                             &none          &none          &none          &none         &kp BSPC      &kp RET            &kp DEL        &none
            >;

            sensor-bindings = <&inc_dec_kp C_VOL_DN C_VOL_UP &inc_dec_kp PG_DN PG_UP>;
        };

		win_number_layer {
            label = "NUM_WIN";
			bindings = <
//                ┌────┬────┬─────┬─────┬────┐           ┌─────┬──────┬──────┬──────┬──────┐
//                │ f1 │ f2 │ f3  │ f4  │ f5 │           │ f6  │  f7  │  f8  │  f9  │ f10  │
//          ┌─────┼────┼────┼─────┼─────┼────┤           ├─────┼──────┼──────┼──────┼──────┼─────┐
//          │     │ `  │ 7  │  8  │  9  │ \  │           │     │      │      │      │      │ f11 │
//    ┌─────┼─────┼────┼────┼─────┼─────┼────┤           ├─────┼──────┼──────┼──────┼──────┼─────┼─────┐
//    │     │     │ '  │ 4  │  5  │  6  │ =  │           │ MEH │ lctl │ lsft │ lalt │ lgui │     │ f12 │
//    └─────┼─────┼────┼────┼─────┼─────┼────┼─────┬─────┼─────┼──────┼──────┼──────┼──────┼─────┼─────┘
//          │     │ [  │ 1  │  2  │  3  │ ]  │     │     │     │      │      │      │      │     │
//          └─────┴────┴────┼─────┼─────┼────┼─────┼─────┼─────┼──────┼──────┼──────┴──────┴─────┘
//                          │     │ esc │ -  │  0  │     │     │      │      │
//                          └─────┴─────┴────┴─────┴─────┴─────┴──────┴──────┘
                  &kp F1      &kp F2   &kp F3   &kp F4    &kp F5                       &kp F6    &kp F7      &kp F8      &kp F9     &kp F10
          &none   &kp GRAVE   &kp N7   &kp N8   &kp N9    &kp BSLH                     &none     &none       &none       &none      &none      &kp F11
  &none   &none   &kp SQT     &kp N4   &kp N5   &kp N6    &kp EQUAL                    &kp MEH   &kp LCTRL   &kp LSHFT   &kp LALT   &kp LGUI   &none     &kp F12
          &none   &kp LBKT    &kp N1   &kp N2   &kp N3    &kp RBKT    &none    &none   &none     &none       &none       &none      &none      &none
                                       &none    &kp ESC   &kp MINUS   &kp N0   &none   &none     &none       &none
			>;

            sensor-bindings = <&inc_dec_kp C_VOL_DN C_VOL_UP &inc_dec_kp C_BRI_DN C_BRI_UP>;
		};

		win_symbol_layer {
            label = "SYM_WIN";
			bindings = <
//                ┌─────┬─────┬─────┬─────┬─────┐           ┌─────┬──────┬──────┬──────┬──────┐
//                │     │     │     │     │     │           │     │      │      │      │      │
//          ┌─────┼─────┼─────┼─────┼─────┼─────┤           ├─────┼──────┼──────┼──────┼──────┼─────┐
//          │     │  ~  │  &  │  *  │  (  │  |  │           │     │      │      │      │      │     │
//    ┌─────┼─────┼─────┼─────┼─────┼─────┼─────┤           ├─────┼──────┼──────┼──────┼──────┼─────┼─────┐
//    │     │     │  "  │  $  │  %  │  ^  │  +  │           │ MEH │ lctl │ lsft │ lalt │ lgui │     │     │
//    └─────┼─────┼─────┼─────┼─────┼─────┼─────┼─────┬─────┼─────┼──────┼──────┼──────┼──────┼─────┼─────┘
//          │     │  {  │  !  │  @  │  #  │  }  │     │     │     │      │      │      │      │     │
//          └─────┴─────┴─────┼─────┼─────┼─────┼─────┼─────┼─────┼──────┼──────┼──────┴──────┴─────┘
//                            │     │ esc │  _  │  )  │     │     │      │      │
//                            └─────┴─────┴─────┴─────┴─────┴─────┴──────┴──────┘
                  &none       &none        &none       &none       &none                          &none     &none       &none       &none      &none
          &none   &kp TILDE   &kp AMPS     &kp ASTRK   &kp LPAR    &kp PIPE                       &none     &none       &none       &none      &none      &none
  &none   &none   &kp DQT     &kp DOLLAR   &kp PRCNT   &kp CARET   &kp PLUS                       &kp MEH   &kp LCTRL   &kp LSHFT   &kp LALT   &kp LGUI   &none   &none
          &none   &kp LBRC    &kp EXCL     &kp AT      &kp HASH    &kp RBRC    &none      &none   &none     &none       &none       &none      &none      &none
                                           &none       &kp ESC     &kp UNDER   &kp RPAR   &none   &none     &none       &none
			>;

            sensor-bindings = <&inc_dec_kp C_VOL_DN C_VOL_UP &inc_dec_kp C_BRI_DN C_BRI_UP>;
        };

		win_gaming_layer {
            label = "GAM_WIN";
			bindings = <
//                            ┌───┬───┬──────────────────┬──────────────┬──────┐                     ┌──────────────┬─────┬──────────────────┬───┬───┐
//                            │ 1 │ 2 │        3         │      4       │  5   │                     │      6       │  7  │        8         │ 9 │ 0 │
//                     ┌──────┼───┼───┼──────────────────┼──────────────┼──────┤                     ├──────────────┼─────┼──────────────────┼───┼───┼───┐
//                     │ tab  │ Q │ W │        E         │      R       │  T   │                     │      Y       │  U  │        I         │ O │ P │ - │
//    ┌────────────────┼──────┼───┼───┼──────────────────┼──────────────┼──────┤                     ├──────────────┼─────┼──────────────────┼───┼───┼───┼───┐
//    │ &td_win_gaming │ lsft │ A │ S │        D         │      F       │  G   │                     │      H       │  J  │        K         │ L │ ; │ ' │ = │
//    └────────────────┼──────┼───┼───┼──────────────────┼──────────────┼──────┼─────┬───────────────┼──────────────┼─────┼──────────────────┼───┼───┼───┼───┘
//                     │ lctl │ Z │ X │        C         │      V       │  B   │ ent │               │      N       │  M  │        ,         │ . │ / │ \ │
//                     └──────┴───┴───┼──────────────────┼──────────────┼──────┼─────┼───────────────┼──────────────┼─────┼──────────────────┼───┴───┴───┘
//                                    │ &td_mac_work_win │ &hm lgui esc │ lalt │ spc │ &trl NUM bspc │ &trl SYM ent │ del │ &td_mac_work_win │
//                                    └──────────────────┴──────────────┴──────┴─────┴───────────────┴──────────────┴─────┴──────────────────┘
                               &kp N1   &kp N2   &kp N3             &kp N4         &kp N5                                 &kp N6         &kp N7    &kp N8             &kp N9    &kp N0
                   &kp TAB     &kp Q    &kp W    &kp E              &kp R          &kp T                                  &kp Y          &kp U     &kp I              &kp O     &kp P      &kp MINUS
  &td_win_gaming   &kp LSHFT   &kp A    &kp S    &kp D              &kp F          &kp G                                  &kp H          &kp J     &kp K              &kp L     &kp SEMI   &kp SQT     &kp EQUAL
                   &kp LCTRL   &kp Z    &kp X    &kp C              &kp V          &kp B      &kp RET     &none           &kp N          &kp M     &kp COMMA          &kp DOT   &kp FSLH   &kp BSLH
                                                 &td_mac_work_win   &hm LGUI ESC   &kp LALT   &kp SPACE   &trl NUM BSPC   &trl SYM RET   &kp DEL   &td_mac_work_win
			>;

            sensor-bindings = <&inc_dec_kp C_VOL_DN C_VOL_UP &inc_dec_kp C_BRI_DN C_BRI_UP>;
		};

		win_aoe2_layer {
            label = "AOE_WIN";
			bindings = <
//                           ┌──────┬───┬──────────────────┬─────┬─────────────┐                     ┌──────────────┬──────────────┬──────────────────┬───┬───┐
//                           │  5   │ 1 │        2         │  3  │      4      │                     │      6       │      7       │        8         │ 9 │ 0 │
//                     ┌─────┼──────┼───┼──────────────────┼─────┼─────────────┤                     ├──────────────┼──────────────┼──────────────────┼───┼───┼───┐
//                     │  `  │ tab  │ Q │        W         │  E  │      R      │                     │      Y       │      U       │        I         │ O │ P │ - │
//    ┌────────────────┼─────┼──────┼───┼──────────────────┼─────┼─────────────┤                     ├──────────────┼──────────────┼──────────────────┼───┼───┼───┼───┐
//    │ &td_win_gaming │ ent │ lsft │ A │        S         │  D  │      F      │                     │      H       │      J       │        K         │ L │ ; │ ' │ = │
//    └────────────────┼─────┼──────┼───┼──────────────────┼─────┼─────────────┼─────┬───────────────┼──────────────┼──────────────┼──────────────────┼───┼───┼───┼───┘
//                     │ f4  │ lctl │ Z │        X         │  C  │      V      │ ent │               │      N       │      M       │        ,         │ . │ / │ \ │
//                     └─────┴──────┴───┼──────────────────┼─────┼─────────────┼─────┼───────────────┼──────────────┼──────────────┼──────────────────┼───┴───┴───┘
//                                      │ &td_mac_work_win │ esc │ &fhm lalt . │ spc │ &trl NUM bspc │ &trl SYM ent │ &hm lgui del │ &td_mac_work_win │
//                                      └──────────────────┴─────┴─────────────┴─────┴───────────────┴──────────────┴──────────────┴──────────────────┘
                               &kp N5      &kp N1   &kp N2             &kp N3    &kp N4                                      &kp N6         &kp N7         &kp N8             &kp N9    &kp N0
                   &kp GRAVE   &kp TAB     &kp Q    &kp W              &kp E     &kp R                                       &kp Y          &kp U          &kp I              &kp O     &kp P      &kp MINUS
  &td_win_gaming   &kp RET     &kp LSHFT   &kp A    &kp S              &kp D     &kp F                                       &kp H          &kp J          &kp K              &kp L     &kp SEMI   &kp SQT     &kp EQUAL
                   &kp F4      &kp LCTRL   &kp Z    &kp X              &kp C     &kp V           &kp RET     &none           &kp N          &kp M          &kp COMMA          &kp DOT   &kp FSLH   &kp BSLH
                                                    &td_mac_work_win   &kp ESC   &fhm LALT DOT   &kp SPACE   &trl NUM BSPC   &trl SYM RET   &hm LGUI DEL   &td_mac_work_win
			>;

            sensor-bindings = <&inc_dec_kp C_VOL_DN C_VOL_UP &inc_dec_kp C_BRI_DN C_BRI_UP>;
		};

    };
};
